# TC3567C register map
File version: 0.1
CPU: CM0 r0p0, little endian, no MPU, no FPU, 4 interrupt priority bits
Registers are 32-bit, read-write, no defined reset value unless marked. A register's access mark holds for its fields unless they carry their own. Offsets are from the block's base; [hi:lo] are bit positions; {n}, {i} and the like mark numbered series.

## BluetoothCounter
Base 0x40040240
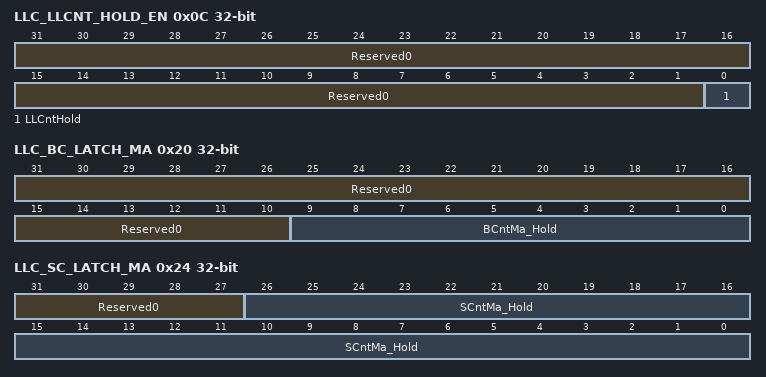
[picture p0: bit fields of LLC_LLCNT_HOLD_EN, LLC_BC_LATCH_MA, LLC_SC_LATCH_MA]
0x0C LLC_LLCNT_HOLD_EN — Hold Bluetooth counter
  [31:1] Reserved0 — Do not change the values.
  [0] LLCntHold — When 0 (or arbitrary value) is set this register, the following registers will hold the values: LLC_BC_LATCH_MA:Master Bit Counter LLC_SC_LATCH_MA:Master Slot Counter Before accessing LLC_BC_LATCH_MA or LLC_SC_LATCH_MA, please set 0 (or arbitrary value) to this register.
0x20 LLC_BC_LATCH_MA ro — Holding Master Bit Counter
  [31:10] Reserved0 — Do not change the values.
  [9:0] BCntMa_Hold rw — Master bit counter value. "Master slot counter" counts up every 1 micro seconds. When this value is 624, this value becomes 0 and SCntMa_Hold value counts up on next count up timing. Before reading this value, please set 0 (or arbitrary value) to LLCntHold.
0x24 LLC_SC_LATCH_MA — Holding Master Slot Counter
  [31:27] Reserved0 — Do not change the values.
  [26:0] SCntMa_Hold — Master slot counter value. "Master slot counter" counts up every 1 slot (625 micro seconds). Before reading this value, please set 0 (or arbitrary value) to LLCntHold.

## PowerManagement — Power Management (GPIO, RTC)
Base 0x40055000
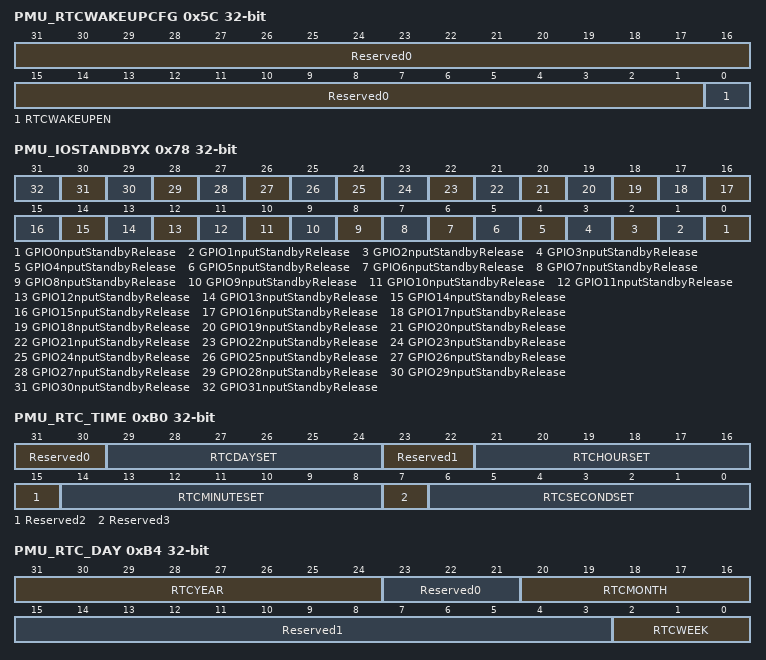
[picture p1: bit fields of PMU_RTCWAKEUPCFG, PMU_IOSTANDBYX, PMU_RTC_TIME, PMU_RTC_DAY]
0x5C PMU_RTCWAKEUPCFG — RTC wakeup config register
  [31:1] Reserved0 — Do not change the values.
  [0] RTCWAKEUPEN — RTC wakeup config 1: Enable wakeup by RTC 0: Disable wakeup by RTC
0x78 PMU_IOSTANDBYX — GPIO input standby
  [n] GPIO{n}nputStandbyRelease (n=0..31) — Input standby release on GPIO{n} 1: Release standby 0: Standby
0xB0 PMU_RTC_TIME — RTC time register
  [31:30] Reserved0 — Do not change the values.
  [29:24] RTCDAYSET — RTC time config of "day" (Binary Coded Decimal) Min: 1 Max: 31
  [23:22] Reserved1 — Do not change the values.
  [21:16] RTCHOURSET — RTC time config of "hour" (Binary Coded Decimal) Min: 0 Max: 23
  [15] Reserved2 — Do not change the values.
  [14:8] RTCMINUTESET — RTC time config of "minute" (Binary Coded Decimal) Min: 0 Max: 59
  [7] Reserved3 — Do not change the values.
  [6:0] RTCSECONDSET — RTC time config of "second" (Binary Coded Decimal) Min: 0 Max: 59
0xB4 PMU_RTC_DAY — RTC date register
  [31:24] RTCYEAR — RTC date config of "year"(Binary Coded Decimal)
  [23:21] Reserved0 — Do not change the values.
  [20:16] RTCMONTH — RTC date config of "month"(Binary Coded Decimal)
  [15:3] Reserved1 — Do not change the values.
  [2:0] RTCWEEK — RTC date config of "week"(Binary Coded Decimal)
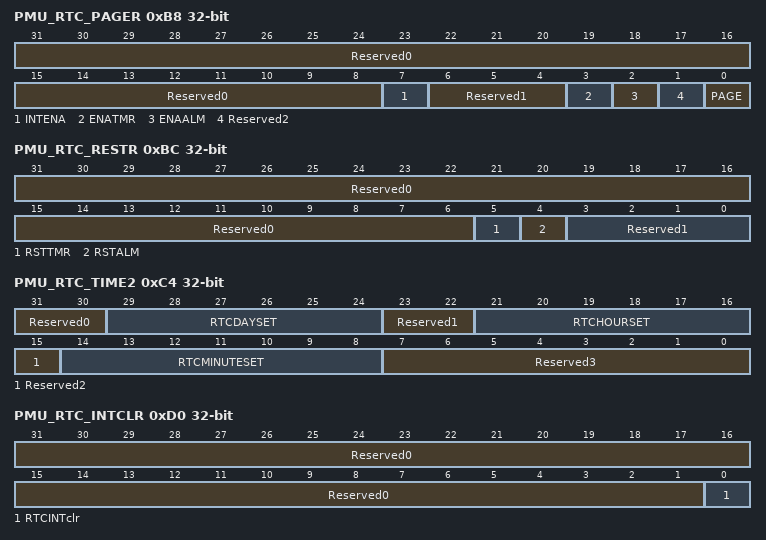
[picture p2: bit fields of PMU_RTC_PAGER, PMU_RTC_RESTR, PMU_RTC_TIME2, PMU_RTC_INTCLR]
0xB8 PMU_RTC_PAGER — RTC control config register
  [31:8] Reserved0 — Do not change the values.
  [7] INTENA — Set interrupt config 0: Disabel 1: Enable
  [6:4] Reserved1 — Always set 0.
  [3] ENATMR — Set clock config 0: Disable 1: Enable
  [2] ENAALM — Set alarm config 0: Disable 1: Enable
  [1] Reserved2 — Do not change the values.
  [0] PAGE — Set Page config 0: Choose Page0 1: Choose Page1
0xBC PMU_RTC_RESTR — RTC reset register
  [31:6] Reserved0 — Always set 0b0000_0000_1100_0001_0000_0000_11
  [5] RSTTMR — Reset clock 0: Not reset 1: Reset If you wan to reset a clock, please set 1 to this value and wait to become 0.
  [4] RSTALM — Reset alarm 0: Not reset 1: Reset If you wan to reset an alarm, please set 1 to this value and wait to become 0.
  [3:0] Reserved1 — Do not change the values.
0xC4 PMU_RTC_TIME2 — RTC time register2
  [31:30] Reserved0 — Do not change the values.
  [29:24] RTCDAYSET — RTC time config of "day" (Binary Coded Decimal) Min: 1 Max: 31
  [23:22] Reserved1 — Do not change the values.
  [21:16] RTCHOURSET — RTC time config of "hour" (Binary Coded Decimal) Min: 0 Max: 23
  [15] Reserved2 — Do not change the values.
  [14:8] RTCMINUTESET — RTC time config of "minute" (Binary Coded Decimal) Min: 0 Max: 59
  [7:0] Reserved3 — Do not change the values.
0xD0 PMU_RTC_INTCLR — RTC interrupt clear register
  [31:1] Reserved0 — Do not change the values.
  [0] RTCINTclr — Clear RTC interrupt 1: Clear 0: Don't care
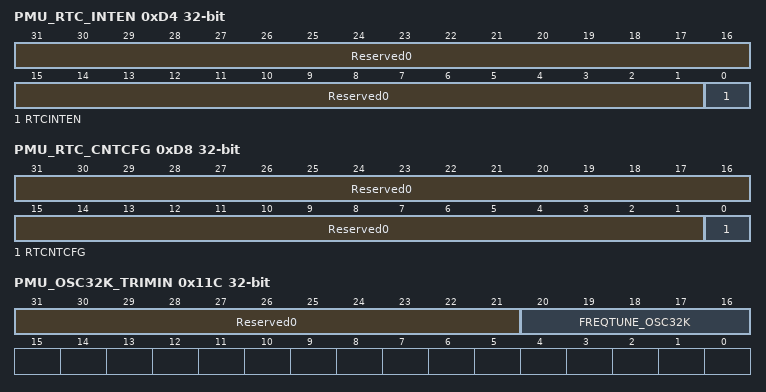
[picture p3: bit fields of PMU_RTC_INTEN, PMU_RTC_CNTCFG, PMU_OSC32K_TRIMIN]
0xD4 PMU_RTC_INTEN — RTC interrupt enable register
  [31:1] Reserved0 — Do not change the values.
  [0] RTCINTEN — Enable RTC interrupt 1: Enable interrupt request 0: Disable interrupt request
0xD8 PMU_RTC_CNTCFG — RTC count cnofig register
  [31:1] Reserved0 — Do not change the values.
  [0] RTCNTCFG — Set RTC config 1: Enable RTC config 0: Disable RTC config
0xE8 PMU_DD_DVSSEL ro — DCDC DVS control register
  [31:0] val — Do not change this value.
0x118 PMU_XOSC_TRIMIN — XOSC trimming register
  [10:4] XO_FREQ_TUNE — Frequency tune value.
0x11C PMU_OSC32K_TRIMIN — OSC32K trimming register
  [31:21] Reserved0 — Do not change the values.
  [20:16] FREQTUNE_OSC32K — Freqency tune value.

## TimerBCG — Timer (BCTimer, GTimer)
Base 0x4004D000
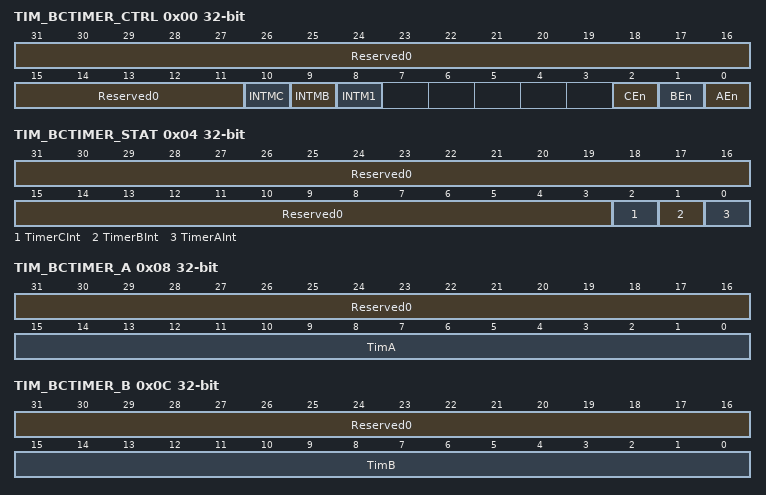
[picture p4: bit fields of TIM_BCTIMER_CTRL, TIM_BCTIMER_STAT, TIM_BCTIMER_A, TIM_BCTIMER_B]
0x00 TIM_BCTIMER_CTRL — Bit Clock Timer Control
  [31:11] Reserved0 ro — Do not change the values.
  [10] INTMC — Timer C Interrupt mask 0: the interrupt is not masked 1: the interutpt is masked
  [9] INTMB — Timer B Interrupt mask 0: the interrupt is not masked 1: the interutpt is masked
  [8] INTM1 — Timer A Interrupt mask 0: the interrupt is not masked 1: the interutpt is masked
  [2] CEn — Enable autoreload feature for timer C 0: Stop when Timer C gets 0. 1: Reload the initial value when Timer C gets 0.
  [1] BEn — Enable autoreload feature for timer B 0: Stop when Timer B gets 0. 1: Reload the initial value when Timer B gets 0.
  [0] AEn — Enable autoreload feature for timer A 0: Stop when Timer A gets 0. 1: Reload the initial value when Timer A gets 0.
0x04 TIM_BCTIMER_STAT — Bit Clock Timer Status
  [31:3] Reserved0 ro — Do not change the values.
  [2] TimerCInt — Interrupt from Timer C 0: No interrupt from Timer C. 1: Interrupt from Timer C exist.
  [1] TimerBInt — Interrupt from Timer B 0: No interrupt from Timer B. 1: Interrupt from Timer B exist.
  [0] TimerAInt — Interrupt from Timer A 0: No interrupt from Timer A. 1: Interrupt from Timer A exist.
0x08 TIM_BCTIMER_A — Bit Clock Timer A control
  [31:16] Reserved0 ro — Do not change the values.
  [15:0] TimA — Start Value Timer A Set the initial value of Timer A.
0x0C TIM_BCTIMER_B — Bit Clock Timer B control
  [31:16] Reserved0 ro — Do not change the values.
  [15:0] TimB — Start Value Timer B Set the initial value of Timer B.
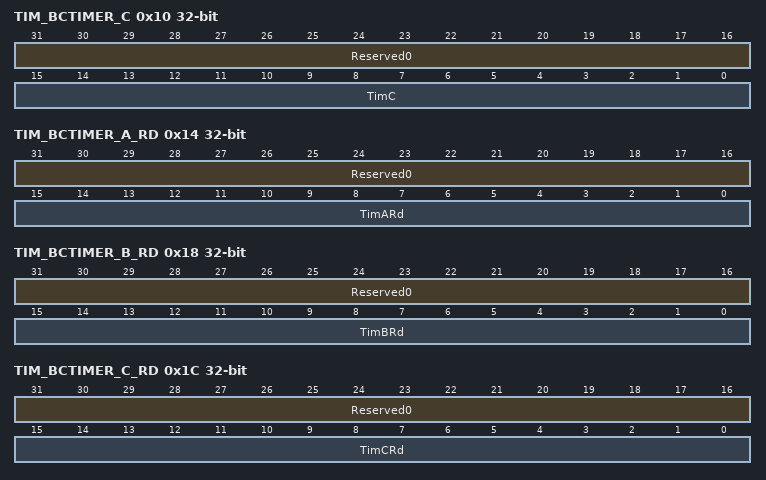
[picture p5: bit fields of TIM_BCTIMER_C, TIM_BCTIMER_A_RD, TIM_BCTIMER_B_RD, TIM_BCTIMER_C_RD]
0x10 TIM_BCTIMER_C — Bit Clock Timer C control
  [31:16] Reserved0 ro — Do not change the values.
  [15:0] TimC — Start Value Timer C Set the initial value of Timer C.
0x14 TIM_BCTIMER_A_RD — Bit Clock Timer A read
  [31:16] Reserved0 ro — Do not change the values.
  [15:0] TimARd — Current Value of Timer A
0x18 TIM_BCTIMER_B_RD — Bit Clock Timer B read
  [31:16] Reserved0 ro — Do not change the values.
  [15:0] TimBRd — Current Value of Timer B
0x1C TIM_BCTIMER_C_RD — Bit Clock Timer C read
  [31:16] Reserved0 ro — Do not change the values.
  [15:0] TimCRd — Current Value of Timer C
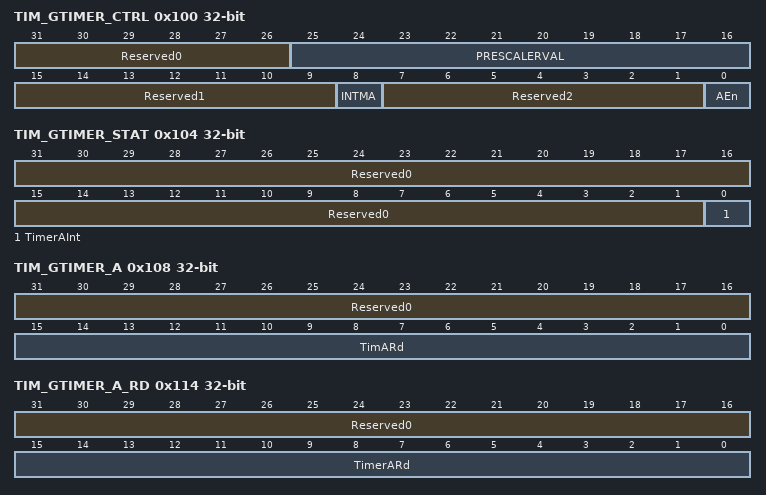
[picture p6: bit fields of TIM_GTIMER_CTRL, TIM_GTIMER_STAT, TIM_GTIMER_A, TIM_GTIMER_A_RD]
0x100 TIM_GTIMER_CTRL — Timer Control
  [31:26] Reserved0 ro — Do not change the values.
  [25:16] PRESCALERVAL — Settings for frequency divider of TimerSCLK to generate timer clock. 0x000 : No divide 0x001 : 1/2 0x002 : 1/3 ........ 0x3ff : 1/1024
  [15:9] Reserved1 ro — Do not change the values.
  [8] INTMA — Timer A Interrupt mask 0: the interrupt is not masked 1: the interutpt is masked
  [7:1] Reserved2 ro — Do not change the values.
  [0] AEn — Enable auto reload feature for Timer A
0x104 TIM_GTIMER_STAT — Timer Status
  [31:1] Reserved0 — Do not change the values.
  [0] TimerAInt — Interrutp bit from Timer A 0: No interrupt from Timer A. 1: Interrupt from Timer A exist.
0x108 TIM_GTIMER_A — Timer Initial Value
  [31:16] Reserved0 ro — Do not change the values.
  [15:0] TimARd — Start Value of TimerA.
0x114 TIM_GTIMER_A_RD — Timer Value read
  [31:16] Reserved0 — Do not change the values.
  [15:0] TimerARd — Current Value of Timer A.
